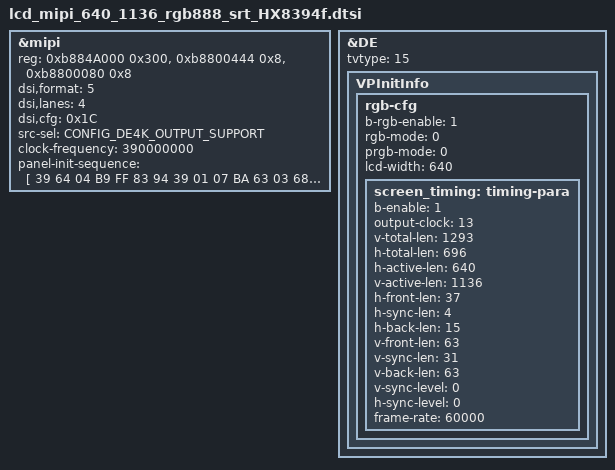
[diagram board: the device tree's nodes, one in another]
&mipi{
	reg = <0xb884A000 0x300>, <0xb8800444 0x8>,<0xb8800080 0x8>;

	/*
		* MIPI_COLOR_RGB565_0	=	0
		* MIPI_COLOR_RGB565_1	=	1
		* MIPI_COLOR_RGB565_2	=	2
		* MIPI_COLOR_RGB666_0	=	3
		* MIPI_COLOR_RGB666_1	=	4
		* MIPI_COLOR_RGB888	=	5
	*/
	dsi,format =<5>;

	dsi,lanes = <4>;

	/*
		* bit 6:5 MIPI_Virtual_Channel_Generic_ID
		* bit 4 :MIPI_CRC
		* bit 3 :MIPI_ECC
		* bit 2 :MIPI_Bus_Turn_request.
		* bit 1 :MIPI_EOTp
		* bit 0 :MIPI_EOTp
		*/
	dsi,cfg = <0x1C>;

	/*
		* 0: E_SRC_SEL_FXDE = 0
		* 1: E_SRC_SEL_4KDE
		* 2: E_SRC_SEL_HDMI_RX
		*/
	src-sel = <CONFIG_DE4K_OUTPUT_SUPPORT>;
	clock-frequency = <390000000>;
	// status = "okay";
};

&DE {
	tvtype = <15>;
	VPInitInfo {
		rgb-cfg{
			b-rgb-enable = <1>;
			/*
			 * 0: MODE_PRGB
			 * 1: MODE_SRGB
			 */
			rgb-mode = <0>;
			/*
			 * 0: MODE_PRGB_888_10bit 
			 * 1: MODE_PRGB_666
			 */
			prgb-mode = <0>; 
			lcd-width = <640>;
			screen_timing: timing-para {
				/* bool type, 0 or 1*/
				b-enable = <1>;
				/*
				 * VPO_RGB_CLOCK_27M = 1,
				 * VPO_RGB_CLOCK_33M = 2,
				 * VPO_RGB_CLOCK_49M = 3,
				 * VPO_RGB_CLOCK_66M = 4,
				 * VPO_RGB_CLOCK_74M = 5,
				 * VPO_RGB_CLOCK_85M = 6,
				 * VPO_RGB_CLOCK_108M = 7,
				 * VPO_RGB_CLOCK_6_6M = 8,
				 * VPO_RGB_CLOCK_9M = 9,
				 * VPO_RGB_CLOCK_39_6M = 10,
				 * VPO_RGB_CLOCK_74_25M = 11,//H1600
				 * VPO_RGB_CLOCK_148_5M = 12,
				 * VPO_RGB_CLOCK_54M = 13,//H1600
				 * VPO_RGB_CLOCK_132M = 14,//H1600
				*/
				output-clock = <13>;

				v-total-len = <1293>;
				h-total-len = <696>;

				h-active-len = <640>;
				v-active-len = <1136>;

				h-front-len = <37>;
				h-sync-len = <4>;
				h-back-len = <15>;

				v-front-len = <63>;
				v-sync-len = <31>;
				v-back-len = <63>;
				
				/* bool type, 0 or 1*/
				v-sync-level = <0>;
				/* bool type, 0 or 1*/
				h-sync-level = <0>;
				frame-rate = <60000>;
			};
		};
	};
};

// #if 1
// &mipi{
// panel-init-sequence = [
// 	39 01 04 B9 FF 83 94 
// 	39 01 07 BA 63 03 68 6B B2 C0 
// 	39 01 0f B1 50 14 74 89 33 54 71 2E 4D 2F 03 30 00 21
// 	39 01 0d B2 00 90 52 0D 0F 3C 00 00 00 00 C0 08 
// 	39 01 16 B4 01 92 41 92 41 92 01 05 A5 35 00 3F 01 92 41 92 41 92 01 05 A5 
// 	39 01 3B E0 00 09 18 22 28 2D 33 34 6D 81 94 93 9B AA AB AA B4 B3 AC B6 C0 5D 59 5A 5B 5A 5B 7F 7F 00 09 17 22 28 2D 33 34 6D 81 94 93 9B AA AB AA B4 B3 AC B6 C0 5D 59 5A 5B 5A 5B 7F 7F 
// 	39 01 22 D3 00 00 07 07 00 00 08 08 32 10 08 00 08 32 14 7C 04 7C 32 10 08 00 00 37 03 0B 0B 27 02 02 27 0D 40 
// 	39 01 2D D5 27 26 25 24 07 06 05 04 03 02 01 00 18 18 18 18 18 18 18 18 19 19 18 18 18 18 18 18 18 18 18 18 18 18 18 18 21 20 23 22 18 18 18 18 
// 	39 01 2C D6 20 21 23 04 05 06 07 00 01 02 03 18 18 18 18 18 18 18 18 18 18 18 18 18 18 18 18 18 18 18 18 18 18 18 18 26 27 24 25 18 18 18 18 
// 	15 14 02 CC 07 
// 	15 14 02 D2 77 
// 	15 14 02 BC 07 
// 	15 14 02 BD 01 
// 	15 14 02 B1 00 
// 	39 01 03 B6 37 37 
// 	39 01 03 C0 1F 73 
// 	05 C8 01 11
// 	05 14 01 29
// 	];
// };
// #endif

&mipi{
panel-init-sequence = [
	39 64 04 B9 FF 83 94 
	39 01 07 BA 63 03 68 6B B2 C0 
	39 01 0f B1 50 14 74 89 33 54 71 2E 4D 2F 03 30 00 21
	39 01 0d B2 00 90 52 0D 0F 3C 00 00 00 00 C0 08 
	39 01 16 B4 01 92 41 92 41 92 01 05 A5 35 00 3F 01 92 41 92 41 92 01 05 A5 
	39 01 3B E0 00 09 18 22 28 2D 33 34 6D 81 94 93 9B AA AB AA B4 B3 AC B6 C0 5D 59 5A 5B 5A 5B 7F 7F 00 09 17 22 28 2D 33 34 6D 81 94 93 9B AA AB AA B4 B3 AC B6 C0 5D 59 5A 5B 5A 5B 7F 7F 
	39 01 22 D3 00 00 07 07 00 00 08 08 32 10 08 00 08 32 14 7C 04 7C 32 10 08 00 00 37 03 0B 0B 27 02 02 27 0D 40 
	39 01 2D D5 27 26 25 24 07 06 05 04 03 02 01 00 18 18 18 18 18 18 18 18 19 19 18 18 18 18 18 18 18 18 18 18 18 18 18 18 21 20 23 22 18 18 18 18 
	39 01 2C D6 20 21 23 04 05 06 07 00 01 02 03 18 18 18 18 18 18 18 18 18 18 18 18 18 18 18 18 18 18 18 18 18 18 18 18 26 27 24 25 18 18 18 18 
	15 14 02 CC 07 
	15 14 02 D2 77 
	15 14 02 BC 07 
	15 14 02 BD 01 
	15 14 02 B1 00 
	15 14 02 BD 00	
	39 01 03 B6 37 37 
	39 01 03 C0 1F 73 
	15 01 02 36 01
	05 C8 01 11
	05 14 01 29
	];
};
